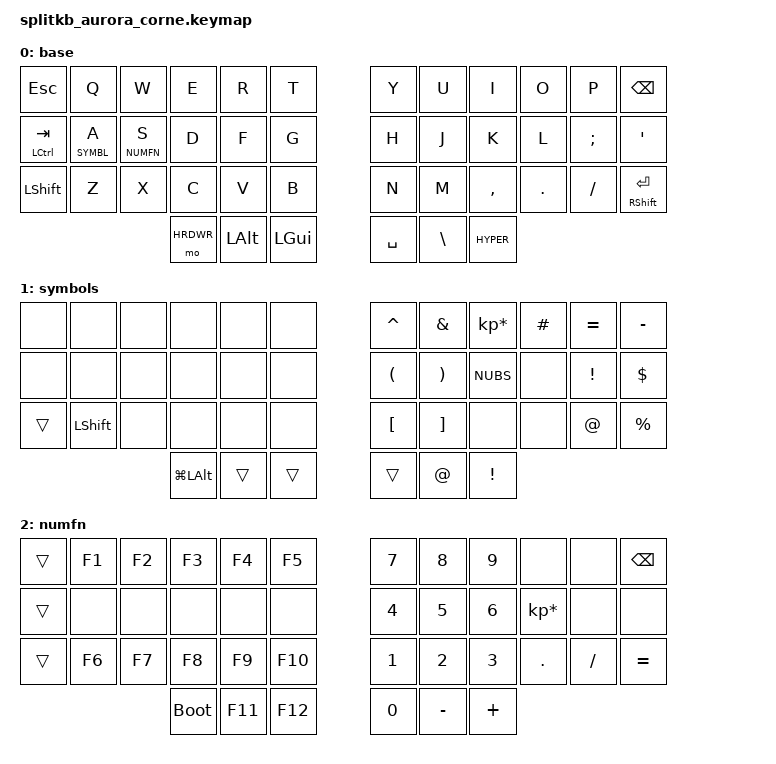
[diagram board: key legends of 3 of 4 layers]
/*
 * Copyright (c) 2020 The ZMK Contributors
 *
 * SPDX-License-Identifier: MIT
 */

#include <behaviors.dtsi>
#include <dt-bindings/zmk/keys.h>
#include <dt-bindings/zmk/rgb.h>
#include <dt-bindings/zmk/bt.h>


#define _BT_SEL_KEYS_ &bt BT_CLR &bt BT_SEL 0 &bt BT_SEL 1 &bt BT_SEL 2 &bt BT_SEL 3 &bt BT_SEL 4
#define _ARROW_KEYS_ &kp LEFT_ARROW   &kp DOWN_ARROW   &kp UP_ARROW   &kp RIGHT_ARROW
#define XXX &none
#define ___ &trans
#define HYPER LC(LG(LA(LSHIFT)))

/*** Global Settings */
#define QUICK_TAP_MS 125

// &lt {  // layer-tap config
//     flavor = "balanced";
//     tapping-term-ms = <150>;
//     quick-tap-ms = <QUICK_TAP_MS>;
// };

/*** Custom key press behaviors */

// homerow mods
// ZMK_BEHAVIOR(hrm, hold_tap,
//     flavor = "balanced";
//     tapping-term-ms = <200>;
//     require-prior-idle-ms = <150>;
//     quick-tap-ms = <QUICK_TAP_MS>;
//     bindings = <&kp>, <&kp>;
// )

/*
 *
 * Note: OS keyboard type must be ISO
 */
#define BASE   0
#define SYMBL  1
#define NUMFN  2
#define HRDWR  3

// &led_strip {
//   chain-length = <12>;
// };
//
// &kscan {
//   debounce-press-ms = <1>;
//   debounce-release-ms = <5>;
// };

/* Keymap */

//            NUHS    BSLH    HASH    NUBS    GRAVE     SHFT APOS
// GB PC         #      #      £         \       `         @
// GB            \      \      £         `       §         "
// US PC         \      \      #         `       §         "
// US            \      \      #         `       §         "
//
// ISO
// =======
// GB PC        #        #     £         \       `         @
// GB           \        \     £        `        §         "
// US PC        \        \     #        `       §          "
// US           \        \     #        `       §          "
// ABC          \        \     #        `       §           "
// ABC+         \         \    #        `       §           "
//
// ANSI
// =======
// GB PC      #        #     £         `       \           @
// GB        \         \     £         §       `           "
// US PC     \         \     #         §       `           "
// US         \        \     #         §       `           "

// NOTE: OSX Must be set to:: ISO Keyboard; GB Input
/ {
  keymap {
    compatible = "zmk,keymap";

    base {
      bindings = <
  // ╭─────────────────┬─────────────────┬─────────────────┬─────────────────┬─────────────────┬─────────────────╮     ╭────────────────┬────────────────┬──────────────┬─────────────────┬──────────┬────────────╮
       &kp  ESC               &kp Q            &kp W             &kp E             &kp R             &kp T                   &kp Y           &kp U         &kp I           &kp O             &kp P       &kp BSPC
  // ├─────────────────┼─────────────────┼─────────────────┼─────────────────┼─────────────────┼─────────────────┤     ├────────────────┼────────────────┼──────────────┼─────────────────┼──────────┼────────────┤
  //                                                                                                                                                                                           ;:         '"
       &mt LCTRL TAB    &lt SYMBL A        &lt NUMFN S           &kp D           &kp F              &kp G                    &kp H           &kp J         &kp K           &kp L             &kp SEMI   &kp APOS
  // ├─────────────────┼─────────────────┼─────────────────┼─────────────────┼─────────────────┼─────────────────┤     ├────────────────┼────────────────┼──────────────┼─────────────────┼──────────┼────────────┤
  //                                                                                                                                                            ,<              .>             /?
       &kp LSHIFT             &kp Z            &kp X            &kp C           &kp V              &kp B                    &kp N           &kp M          &kp COMMA       &kp DOT           &kp FSLH   &mt RSHIFT RETURN
  // ╰─────────────────┼─────────────────┼─────────────────┼─────────────────┼─────────────────┼─────────────────┤     ├────────────────┼────────────────┼──────────────┼─────────────────┼──────────┼────────────╯
                                                               &mo HRDWR        &kp LALT         &kp LGUI                   &kp SPACE       &kp BSLH       &kp HYPER
  //                                                       ╰─────────────────┴─────────────────┴─────────────────╯     ╰────────────────┴────────────────┴──────────────╯
      >;
    };

    symbols {
      bindings = <
  // ╭─────────────────┬─────────────────┬─────────────────┬─────────────────┬─────────────────┬─────────────────╮     ╭────────────────┬────────────────┬──────────────┬─────────────────┬──────────┬────────────╮
  //                                                                                                                            ^                &               *               £              =+           -
            XXX               XXX               XXX              XXX                XXX               XXX                   &kp CARET        &kp AMPS      &kp KP_MULTIPLY   &kp POUND    &kp EQUAL   &kp MINUS
  // ├─────────────────┼─────────────────┼─────────────────┼─────────────────┼─────────────────┼─────────────────┤     ├────────────────┼────────────────┼──────────────┼─────────────────┼──────────┼────────────┤
  //                                                                                                                             (               )               `~                             !          $
            XXX               XXX               XXX              XXX                XXX               XXX                   &kp LPAR        &kp RPAR          &kp NUBS          XXX         &kp EXCL    &kp DLLR
  // ├─────────────────┼─────────────────┼─────────────────┼─────────────────┼─────────────────┼─────────────────┤     ├────────────────┼────────────────┼──────────────┼─────────────────┼──────────┼────────────┤
  //                                                                                                                            [{              ]}                                             @           %
            ___           &kp LSHIFT              XXX               XXX             XXX               XXX                   &kp LBKT         &kp RBKT          XXX              XXX         &kp AT      &kp PRCNT
  // ╰─────────────────┼─────────────────┼─────────────────┼─────────────────┼─────────────────┼─────────────────┤     ├────────────────┼────────────────┼──────────────┼─────────────────┼──────────┼────────────╯
                                                              &kp LG(LALT)          ___               ___                     ___            &kp AT          &kp EXCL
  //                                                       ╰─────────────────┴─────────────────┴─────────────────╯     ╰────────────────┴────────────────┴──────────────╯
      >;
    };

    numfn {
      bindings = <
  // ╭─────────────────┬─────────────────┬─────────────────┬─────────────────┬─────────────────┬─────────────────╮     ╭────────────────┬────────────────┬──────────────┬─────────────────┬──────────┬────────────╮
       ___                    &kp F1            &kp F2            &kp F3            &kp F4            &kp F5                &kp N7           &kp N8          &kp N9            XXX           XXX        &kp BSPC
  // ├─────────────────┼─────────────────┼─────────────────┼─────────────────┼─────────────────┼─────────────────┤     ├────────────────┼────────────────┼──────────────┼─────────────────┼──────────┼────────────┤
       ___                    XXX               XXX               XXX               XXX               XXX                   &kp N4           &kp N5          &kp N6       &kp KP_MULTIPLY    XXX        XXX
  // ├─────────────────┼─────────────────┼─────────────────┼─────────────────┼─────────────────┼─────────────────┤     ├────────────────┼────────────────┼──────────────┼─────────────────┼──────────┼────────────┤
       ___                    &kp F6            &kp F7            &kp F8            &kp F9            &kp F10               &kp N1           &kp N2          &kp N3          &kp DOT        &kp FSLH   &kp EQUAL
  // ╰─────────────────┼─────────────────┼─────────────────┼─────────────────┼─────────────────┼─────────────────┤     ├────────────────┼────────────────┼──────────────┼─────────────────┼──────────┼────────────╯
                                                              &bootloader           &kp F11           &kp F12               &kp N0         &kp MINUS        &kp PLUS
  //                                                       ╰─────────────────┴─────────────────┴─────────────────╯     ╰────────────────┴────────────────┴──────────────╯
      >;
    };

    hardware_w_nav {
      bindings = <
  // ╭─────────────────┬─────────────────┬─────────────────┬─────────────────┬─────────────────┬─────────────────╮     ╭────────────────┬────────────────┬──────────────┬─────────────────┬──────────┬────────────╮
       &rgb_ug RGB_BRI   &rgb_ug RGB_SAI   &rgb_ug RGB_HUI   &rgb_ug RGB_EFF   &rgb_ug RGB_SPI   &rgb_ug RGB_TOG         &kp C_VOL_DN     &kp K_MUTE       &kp C_VOL_UP   &kp C_PREV        &kp C_PP   &kp C_NEXT
  // ├─────────────────┼─────────────────┼─────────────────┼─────────────────┼─────────────────┼─────────────────┤     ├────────────────┼────────────────┼──────────────┼─────────────────┼──────────┼────────────┤
       &rgb_ug RGB_BRD   &rgb_ug RGB_SAD   &rgb_ug RGB_HUD   &rgb_ug RGB_EFR   &rgb_ug RGB_SPD   XXX                                               _ARROW_KEYS_                               XXX         XXX
  // ├─────────────────┼─────────────────┼─────────────────┼─────────────────┼─────────────────┼─────────────────┤     ├────────────────┼────────────────┼──────────────┼─────────────────┼──────────┼────────────┤
                                                    _BT_SEL_KEYS_                                                             XXX               XXX             XXX             XXX           XXX         XXX
  // ╰─────────────────┼─────────────────┼─────────────────┼─────────────────┼─────────────────┼─────────────────┤     ├────────────────┼────────────────┼──────────────┼─────────────────┼──────────┼────────────╯
                                                             XXX               ___               ___                          XXX               XXX        &bootloader
  //                                                       ╰─────────────────┴─────────────────┴─────────────────╯     ╰────────────────┴────────────────┴──────────────╯
      >;
    };
  };
};

// vi: ft=devicetree
